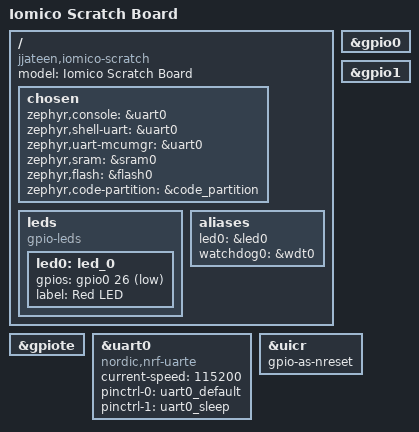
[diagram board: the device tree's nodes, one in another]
/*
 * SPDX-License-Identifier: Apache-2.0
 */

/dts-v1/;
#include <nordic/nrf52840_qiaa.dtsi>
#include <nordic/nrf52840_partition_uf2_sdv7.dtsi>
#include "iomico_scratch-pinctrl.dtsi"

/ {
	model = "Iomico Scratch Board";
	compatible = "jjateen,iomico-scratch";

	chosen {
		zephyr,console = &uart0;
		zephyr,shell-uart = &uart0;
		zephyr,uart-mcumgr = &uart0;
		zephyr,sram = &sram0;
		zephyr,flash = &flash0;
		zephyr,code-partition = &code_partition;
	};

	leds {
		compatible = "gpio-leds";
		led0: led_0 {
			gpios = <&gpio0 26 GPIO_ACTIVE_LOW>;
			label = "Red LED";
		};
	};

	aliases {
		led0 = &led0;
		watchdog0 = &wdt0;
	};
};

&gpiote {
	status = "okay";
};

&gpio0 {
	status = "okay";
};

&gpio1 {
	status = "okay";
};

&uart0 {
	compatible = "nordic,nrf-uarte";
	status = "okay";
	current-speed = <115200>;
	pinctrl-0 = <&uart0_default>;
	pinctrl-1 = <&uart0_sleep>;
	pinctrl-names = "default", "sleep";
};

&uicr {
	gpio-as-nreset;
};
